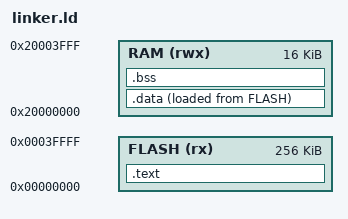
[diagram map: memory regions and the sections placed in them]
MEMORY {
    RAM (rwx) : ORIGIN = 0x20000000, LENGTH = 16K
    FLASH (rx) : ORIGIN = 0x00000000, LENGTH = 256K
}

_estack = ORIGIN(RAM) + LENGTH(RAM);

SECTIONS {
    .text : {
        KEEP(*(.isr_vector))
        *(.text*)
        *(.rodata*)
        . = ALIGN(4);
    } > FLASH

    _sidata = LOADADDR(.data);

    .data : ALIGN(4) {
        _sdata = .;
        *(.data*)
        . = ALIGN(4);
        _edata = .;
    } > RAM AT > FLASH

    .bss : ALIGN(4) {
        _sbss = .;
        *(.bss*)
        *(COMMON)
        . = ALIGN(4);
        _ebss = .;
    } > RAM

    end = .;
}
